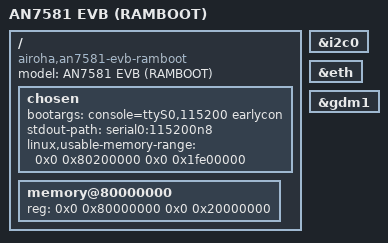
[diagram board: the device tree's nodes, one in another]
// SPDX-License-Identifier: (GPL-2.0-only OR BSD-2-Clause)
/dts-v1/;

#include <dt-bindings/leds/common.h>
#include <dt-bindings/gpio/gpio.h>
#include <dt-bindings/input/input.h>
#include "an7581.dtsi"

/ {
	model = "AN7581 EVB (RAMBOOT)";
	compatible = "airoha,an7581-evb-ramboot",
		     "airoha,an7581",
		     "airoha,en7581";

	chosen {
		bootargs = "console=ttyS0,115200 earlycon";
		stdout-path = "serial0:115200n8";
		linux,usable-memory-range = <0x0 0x80200000 0x0 0x1fe00000>;
	};

	memory@80000000 {
		device_type = "memory";
		reg = <0x0 0x80000000 0x0 0x20000000>;
	};
};

&i2c0 {
	status = "okay";
};

&eth {
	status = "okay";
};

&gdm1 {
	status = "okay";
};
